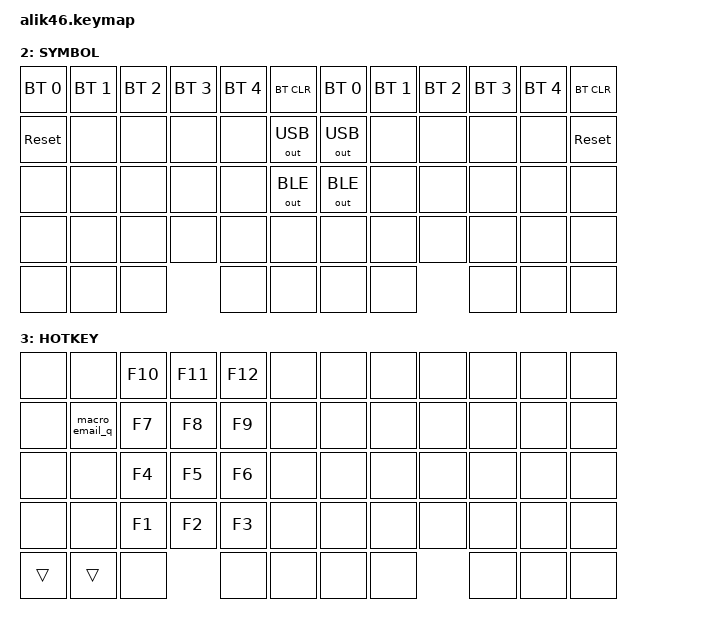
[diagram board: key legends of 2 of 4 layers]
#include <behaviors.dtsi>
#include <dt-bindings/zmk/bt.h>
#include <dt-bindings/zmk/keys.h>
#include <dt-bindings/zmk/outputs.h>

#define DEFAULT 0
#define NUMBER  1
#define SYMBOL  2
#define HOTKEY  3

#define AS(keycode) &as LS(keycode) keycode

/ {
    

    macros {
        macro_email_q: macro_email_q {
            // 714448168@qq.com

            label = "MACRO_EMAIL_QQ";
            compatible = "zmk,behavior-macro";
            #binding-cells = <0>;
            bindings = <&kp N7 &kp N1 &kp N4 &kp N4 &kp N4 &kp N8 &kp N1 &kp N6 &kp N8 &kp AT &kp Q &kp Q &kp DOT &kp C &kp O &kp M>;
        };

        GUANJIANCI: GUANJIANCI {
            compatible = "zmk,behavior-macro";
            label = "new_macro";
            #binding-cells = <0>;
            bindings = <&kp LSHIFT &kp LBKT &kp RBKT &kp LEFT &kp LSHIFT>;
        };

         macro_todo: macro_todo {
            compatible = "zmk,behavior-macro";
            label = "macro_todo";
            #binding-cells = <0>;
            bindings = <&kp LBKT &kp RBKT &kp LEFT>;
        };
    };

    combos {
        compatible = "zmk,combos";

        combo_caps {
            timeout-ms = <50>;
            key-positions = <0 1>; // KP: VB
            bindings = <&kp CAPS>; // }{
            layers = <0 1 2 3 4 5>;
        };
        combo_lbrc {
            timeout-ms = <50>;
            key-positions = <4 5>; // KP: VB
            bindings = <&mt RBRC LBRC>; // }{
            layers = <0 1 2 3 4 5>;
        };

        combo_rbrc {
            timeout-ms = <50>;
            key-positions = <6 7>; // KP: NM
            bindings = <&kp RBRC>; // }
            layers = <0 1 2 3 4 5>;
        }; 

        combo_lpar {
            timeout-ms = <50>;
            key-positions = <16 17>; // KP: FG
            bindings = <&mt RPAR LPAR>; // )(
            layers = <0 1 2 3 4 5>;
        };

        combo_equal {
            timeout-ms = <50>;
            key-positions = <17 18>; // KP: FG
            bindings = <&mt PLUS EQUAL>; // )(
            layers = <0 1 2 3 4 5>;
        };

        combo_rpar {
            timeout-ms = <50>;
            key-positions = <18 19>; // KP: HJ
            bindings = <&kp RPAR>; // )
            layers = <0 1 2 3 4 5>;
        };

        combo_lbkt {
            timeout-ms = <50>;
            key-positions = <28 29>; // KP: RT
            bindings = <&mt RBKT LBKT>; // ][ // 可以用CMD+这个单手返回到代码上一个编辑的地方 或者网页返回
            layers = <0 1 2 3 4 5>;
        };

        combo_grave {
            timeout-ms = <50>;
            key-positions = <29 30>; // KP: RT
            bindings = <&mt GRAVE TILDE>; // ][ // 可以用CMD+这个单手返回到代码上一个编辑的地方 或者网页返回
            layers = <0 1 2 3 4 5>;
        };

        combo_rbkt {
            timeout-ms = <50>;
            key-positions = <30 31>; // KP: YU
            bindings = <&kp RBKT>; // ]
            layers = <0 1 2 3 4 5>;
        };

        lup {
            bindings = <&kp UP>;
            key-positions = <3 4>;
            layers = <0>;
            timeout-ms = <50>;
        };

        ldown {
            bindings = <&kp DOWN>;
            key-positions = <27 28>;
            timeout-ms = <50>;
            layers = <0>;
        };

        lleft {
            bindings = <&kp LEFT>;
            key-positions = <14 15>;
            layers = <0>;
            timeout-ms = <50>;
        };

        lright {
            bindings = <&kp RIGHT>;
            key-positions = <15 16>;
            layers = <0>;
            timeout-ms = <50>;
        };

        rup {
            bindings = <&kp UP>;
            key-positions = <7 8>;
            layers = <0>;
            timeout-ms = <50>;
        };

        rdown {
            bindings = <&kp DOWN>;
            key-positions = <31 32>;
            timeout-ms = <50>;
            layers = <0>;
        };

        rleft {
            bindings = <&kp LEFT>;
            key-positions = <19 20>;
            layers = <0>;
            timeout-ms = <50>;
        };

        rright {
            bindings = <&kp RIGHT>;
            key-positions = <21 22>;
            layers = <0>;
            timeout-ms = <50>;
        };
    };


    keymap {
        compatible = "zmk,keymap";

        default_layer {
            label = "DEFAULT";
            bindings = <    
            &lt 1 ESC     &kp Q   &kp W          &kp E         &kp R      &kp T            &kp Y          &kp U      &kp I      &kp O      &kp P     &lt 2 MINUS
            &lt 2 TAB      &kp A   &kp S          &kp D         &kp F      &kp G            &kp H          &kp J      &kp K      &kp L      &kp SEMI  &kp SQT
            &kp LSHFT      &kp Z   &kp X          &kp C         &kp V      &kp B            &kp N      &kp M      &kp COMMA  &kp DOT    &kp FSLH      &kp RSHIFT
            &kp LCTRL      &kp LWIN  &kp LEFT_ALT    &mt LCTRL RETURN       &mo 1            &kp BACKSPACE  &kp SPACE            &kp BSLH   &kp GRAVE    &kp EQUAL    
            >;
        };

        number_layer {
            label = "NUMBER";
            bindings = <
            &kp F1    &kp F2    &kp F3    &kp F4     &kp F5     &kp F6        &kp F7     &kp F8     &kp F9      &kp F10      &kp F11 &kp F12 
            &none     &kp N1    &kp N2    &kp N3     &kp N4     &kp N5        &kp N6     &kp N7     &kp N8      &kp N9       &kp N0  &kp EQUAL
            &none     &kp LEFT  &kp UP  &kp DOWN   &kp RIGHT    &GUANJIANCI   &macro_todo      &kp KP_N4  &kp KP_N5   &kp KP_N6    &none   &none
            &kp LSHFT  &kp C_VOL_DN  &kp C_VOL_UP           &none      &none         &none      &none                  &kp KP_N1    &none   &none
            >;
        };

        symbol_layer {
            label = "SYMBOL";
            bindings = <
            &bt BT_SEL 0  &bt BT_SEL 1  &bt BT_SEL 2  &bt BT_SEL 3  &bt BT_SEL 4  &bt BT_CLR     &bt BT_SEL 0  &bt BT_SEL 1  &bt BT_SEL 2  &bt BT_SEL 3  &bt BT_SEL 4  &bt BT_CLR
            &sys_reset    &none         &none         &none         &none         &out OUT_USB   &out OUT_USB  &none         &none         &none         &none         &sys_reset
            &none         &none         &none         &none         &none         &out OUT_BLE   &out OUT_BLE  &none         &none         &none         &none         &none
            &none         &none         &none         &none         &none         &none          &none         &none         &none         &none         &none         &none
            &none         &none         &none                       &none         &none          &none         &none                       &none         &none         &none
            >;
        };

        hotkey_layer {
            label = "HOTKEY";
            bindings = <
            &none  &none           &kp F10  &kp F11  &kp F12  &none  &none  &none  &none  &none  &none  &none
            &none  &macro_email_q  &kp F7   &kp F8   &kp F9   &none  &none  &none  &none  &none  &none  &none
            &none  &none           &kp F4   &kp F5   &kp F6   &none  &none  &none  &none  &none  &none  &none
            &none  &none           &kp F1   &kp F2   &kp F3   &none  &none  &none  &none  &none  &none  &none
            &trans  &trans           &none             &none    &none  &none  &none         &none  &none  &none
            >;
        };
    };
};
